# N32G457 register map
Vendor: NSING TECHNOLOGIES PTE. LTD.; File version: 1.0
Registers are 32-bit, read-write, reset 0x0 unless marked. A register's access mark holds for its fields unless they carry their own. Offsets are from the block's base; [hi:lo] are bit positions; {n}, {i} and the like mark numbered series; 'fields as' and 'values as' point back to an identical list.

## USART1 — Universal synchronous asynchronous receiver transmitter
Base 0x40013800
Same registers: USART2 0x40004400, USART3 0x40004800, UART4 0x40004C00, UART5 0x40005000, UART6 0x40015000, UART7 0x40015400
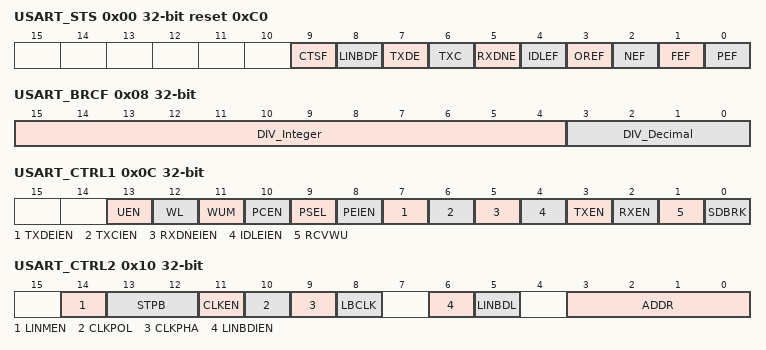
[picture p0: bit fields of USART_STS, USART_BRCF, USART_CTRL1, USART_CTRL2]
0x00 USART_STS reset 0xC0
  [9] CTSF, [8] LINBDF, [7] TXDE, [6] TXC, [5] RXDNE, [4] IDLEF, [3] OREF, [2] NEF, [1] FEF, [0] PEF
0x04 USART_DAT
  [8:0] DATV
0x08 USART_BRCF
  [15:4] DIV_Integer, [3:0] DIV_Decimal
0x0C USART_CTRL1
  [13] UEN, [12] WL, [11] WUM, [10] PCEN, [9] PSEL, [8] PEIEN, [7] TXDEIEN, [6] TXCIEN, [5] RXDNEIEN, [4] IDLEIEN, [3] TXEN, [2] RXEN, [1] RCVWU, [0] SDBRK
0x10 USART_CTRL2
  [14] LINMEN, [13:12] STPB, [11] CLKEN, [10] CLKPOL, [9] CLKPHA, [8] LBCLK, [6] LINBDIEN, [5] LINBDL, [3:0] ADDR
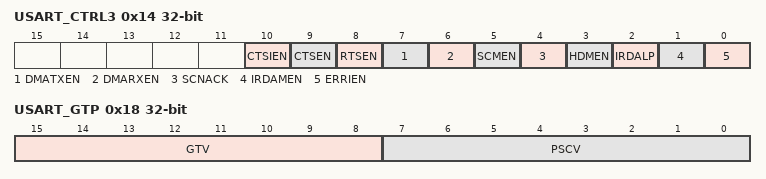
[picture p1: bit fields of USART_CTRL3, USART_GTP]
0x14 USART_CTRL3
  [10] CTSIEN, [9] CTSEN, [8] RTSEN, [7] DMATXEN, [6] DMARXEN, [5] SCMEN, [4] SCNACK, [3] HDMEN, [2] IRDALP, [1] IRDAMEN, [0] ERRIEN
0x18 USART_GTP
  [15:8] GTV, [7:0] PSCV

## USB — Universal serial bus full-speed device interface
Base 0x40005C00
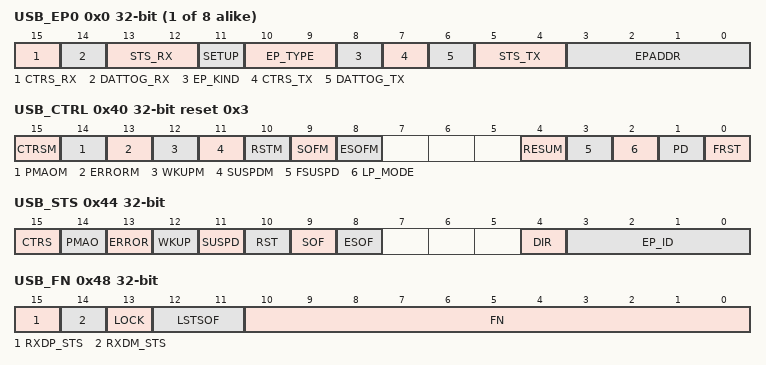
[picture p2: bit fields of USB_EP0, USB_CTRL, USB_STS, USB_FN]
{0x0+4i} USB_EP{i} (i=0..7)
  [15] CTRS_RX, [14] DATTOG_RX, [13:12] STS_RX, [11] SETUP, [10:9] EP_TYPE, [8] EP_KIND, [7] CTRS_TX, [6] DATTOG_TX, [5:4] STS_TX, [3:0] EPADDR
0x40 USB_CTRL reset 0x3
  [15] CTRSM, [14] PMAOM, [13] ERRORM, [12] WKUPM, [11] SUSPDM, [10] RSTM, [9] SOFM, [8] ESOFM, [4] RESUM, [3] FSUSPD, [2] LP_MODE, [1] PD, [0] FRST
0x44 USB_STS
  [15] CTRS, [14] PMAO, [13] ERROR, [12] WKUP, [11] SUSPD, [10] RST, [9] SOF, [8] ESOF, [4] DIR, [3:0] EP_ID
0x48 USB_FN
  [15] RXDP_STS, [14] RXDM_STS, [13] LOCK, [12:11] LSTSOF, [10:0] FN
0x4C USB_ADDR
  [6:0] ADDR
0x50 USB_BUFTAB
  [15:3] BUFTAB

## OPAMP — operational amplifier
Base 0x40002000
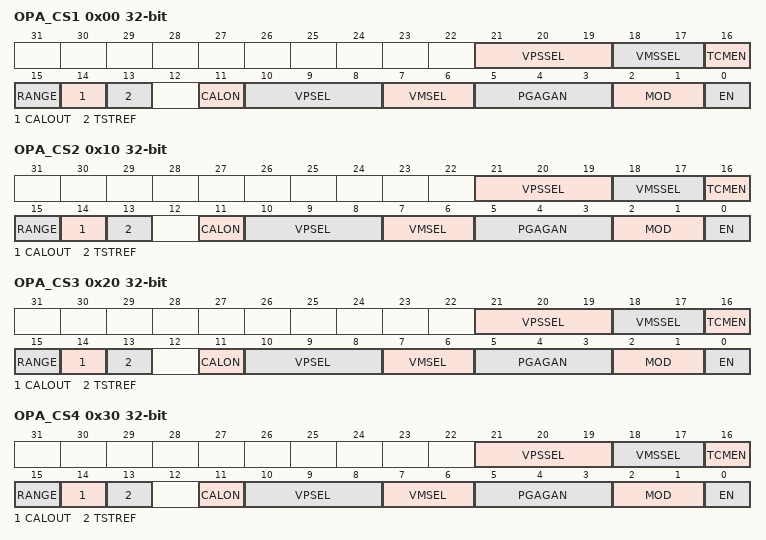
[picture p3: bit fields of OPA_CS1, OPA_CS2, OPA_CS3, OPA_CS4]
0x00 OPA_CS1
  [21:19] VPSSEL, [18:17] VMSSEL, [16] TCMEN, [15] RANGE, [14] CALOUT, [13] TSTREF, [11] CALON, [10:8] VPSEL, [7:6] VMSEL, [5:3] PGAGAN, [2:1] MOD, [0] EN
0x10 OPA_CS2
  fields as OPA_CS1
0x20 OPA_CS3
  fields as OPA_CS1
0x30 OPA_CS4
  fields as OPA_CS1
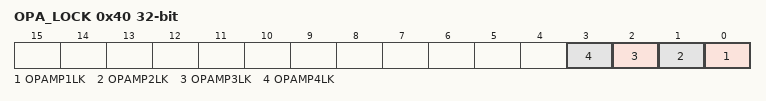
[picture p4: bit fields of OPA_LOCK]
0x40 OPA_LOCK
  [n-1] OPAMP{n}LK (n=1..4)

## COMP — comparator
Base 0x40002400
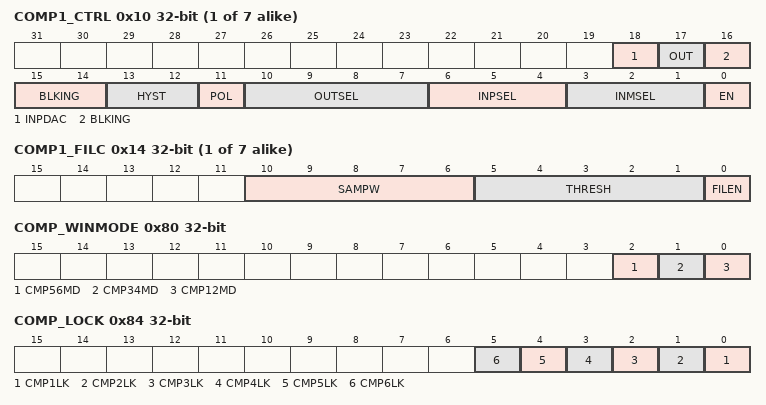
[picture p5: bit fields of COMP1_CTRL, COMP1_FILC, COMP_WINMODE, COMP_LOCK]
{0x0+0x10*i} COMP{i}_CTRL (i=1..7)
  [18] INPDAC, [17] OUT ro, [16:14] BLKING, [13:12] HYST, [11] POL, [10:7] OUTSEL, [6:4] INPSEL, [3:1] INMSEL, [0] EN
{0x4+0x10*i} COMP{i}_FILC (i=1..7)
  [10:6] SAMPW, [5:1] THRESH, [0] FILEN
{0x8+0x10*i} COMP{i}_FILP (i=1..7)
  [15:0] CLKPSC
0x80 COMP_WINMODE
  [2] CMP56MD, [1] CMP34MD, [0] CMP12MD
0x84 COMP_LOCK
  [n-1] CMP{n}LK (n=1..6)
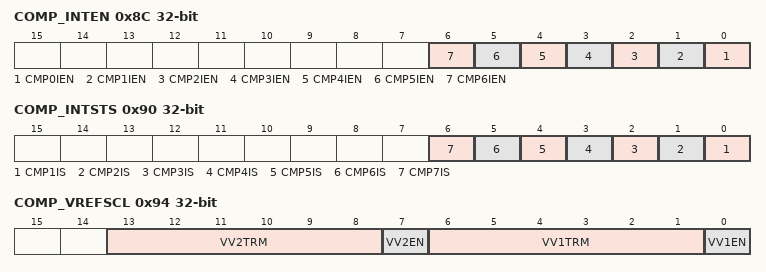
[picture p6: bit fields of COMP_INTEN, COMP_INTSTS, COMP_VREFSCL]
0x8C COMP_INTEN
  [n] CMP{n}IEN (n=0..6)
0x90 COMP_INTSTS
  [n-1] CMP{n}IS (n=1..7)
0x94 COMP_VREFSCL
  [13:8] VV2TRM, [7] VV2EN, [6:1] VV1TRM, [0] VV1EN

## TSC — touch screen control
Base 0x40003400
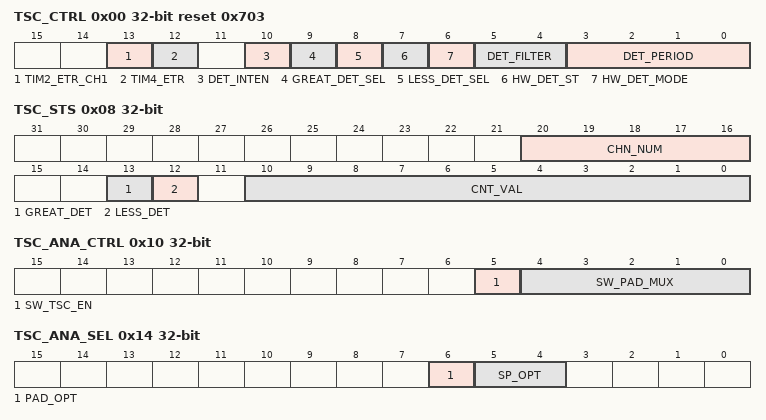
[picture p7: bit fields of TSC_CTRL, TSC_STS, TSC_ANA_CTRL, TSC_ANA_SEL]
0x00 TSC_CTRL reset 0x703
  [13] TIM2_ETR_CH1, [12] TIM4_ETR, [10] DET_INTEN, [9] GREAT_DET_SEL, [8] LESS_DET_SEL, [7] HW_DET_ST, [6] HW_DET_MODE, [5:4] DET_FILTER, [3:0] DET_PERIOD
0x04 TSC_CHNEN
  [23:0] CHN_SEL
0x08 TSC_STS
  [20:16] CHN_NUM, [13] GREAT_DET, [12] LESS_DET, [10:0] CNT_VAL
0x10 TSC_ANA_CTRL
  [5] SW_TSC_EN, [4:0] SW_PAD_MUX
0x14 TSC_ANA_SEL
  [6] PAD_OPT, [5:4] SP_OPT
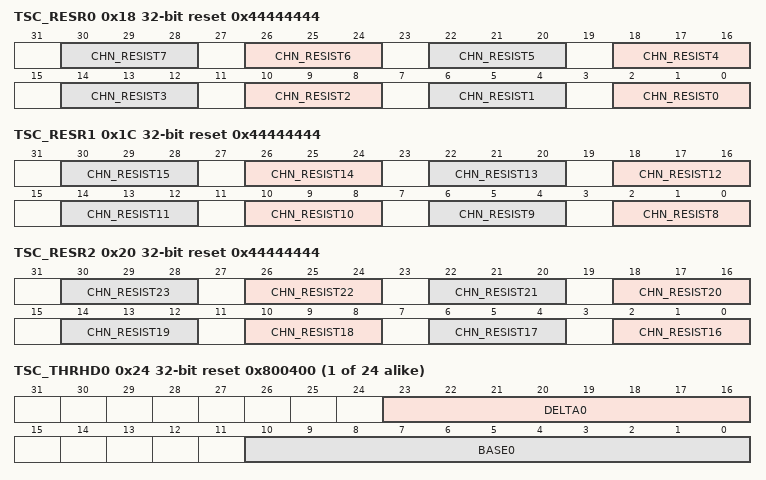
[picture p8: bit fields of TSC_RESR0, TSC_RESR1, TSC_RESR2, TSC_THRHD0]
0x18 TSC_RESR0 reset 0x44444444
  [4n+2:4n] CHN_RESIST{n} (n=0..7)
0x1C TSC_RESR1 reset 0x44444444
  [4n-30:4n-32] CHN_RESIST{n} (n=8..15)
0x20 TSC_RESR2 reset 0x44444444
  [4n-62:4n-64] CHN_RESIST{n} (n=16..23)
{0x24+4i} TSC_THRHD{i} reset 0x800400 (i=0..23)
  [23:16] DELTA{i}, [10:0] BASE{i}

## ETH — Ethernet: media access control
Base 0x40028000
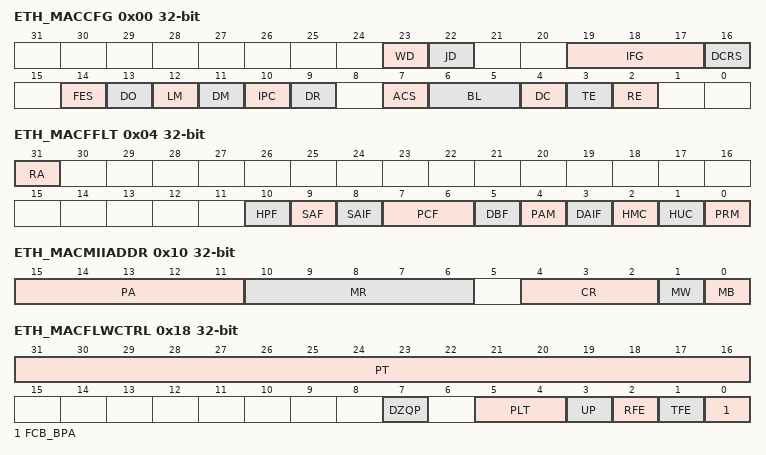
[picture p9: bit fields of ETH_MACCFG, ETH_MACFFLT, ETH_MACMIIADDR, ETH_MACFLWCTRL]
0x00 ETH_MACCFG
  [23] WD, [22] JD, [19:17] IFG, [16] DCRS, [14] FES, [13] DO, [12] LM, [11] DM, [10] IPC, [9] DR, [7] ACS, [6:5] BL, [4] DC, [3] TE, [2] RE
0x04 ETH_MACFFLT
  [31] RA, [10] HPF, [9] SAF, [8] SAIF, [7:6] PCF, [5] DBF, [4] PAM, [3] DAIF, [2] HMC, [1] HUC, [0] PRM
0x08 ETH_MACHASHHI
  [31:0] HTH
0x0C ETH_MACHASHLO
  [31:0] HTL
0x10 ETH_MACMIIADDR
  [15:11] PA, [10:6] MR, [4:2] CR, [1] MW, [0] MB
0x14 ETH_MACMIIDAT
  [15:0] MD
0x18 ETH_MACFLWCTRL
  [31:16] PT, [7] DZQP, [5:4] PLT, [3] UP, [2] RFE, [1] TFE, [0] FCB_BPA
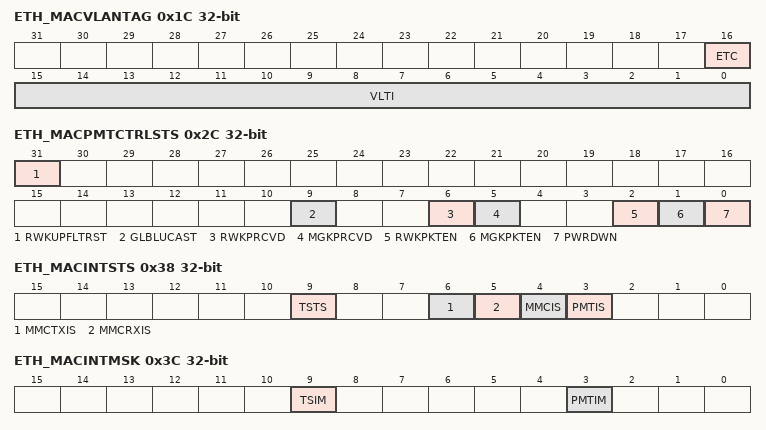
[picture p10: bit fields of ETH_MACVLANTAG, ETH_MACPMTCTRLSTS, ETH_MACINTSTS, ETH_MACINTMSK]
0x1C ETH_MACVLANTAG
  [16] ETC, [15:0] VLTI
0x28 ETH_MACRMTWUFRMFLT
  [31:0] DAT
0x2C ETH_MACPMTCTRLSTS
  [31] RWKUPFLTRST, [9] GLBLUCAST, [6] RWKPRCVD, [5] MGKPRCVD, [2] RWKPKTEN, [1] MGKPKTEN, [0] PWRDWN
0x38 ETH_MACINTSTS
  [9] TSTS, [6] MMCTXIS, [5] MMCRXIS, [4] MMCIS, [3] PMTIS
0x3C ETH_MACINTMSK
  [9] TSIM, [3] PMTIM
0x40 ETH_MACADDR0HI reset 0xFFFF
  [15:0] ADDRHI
{0x44+8i} ETH_MACADDR{i}LO reset 0xFFFFFFFF (i=0..3)
  [31:0] ADDRLO
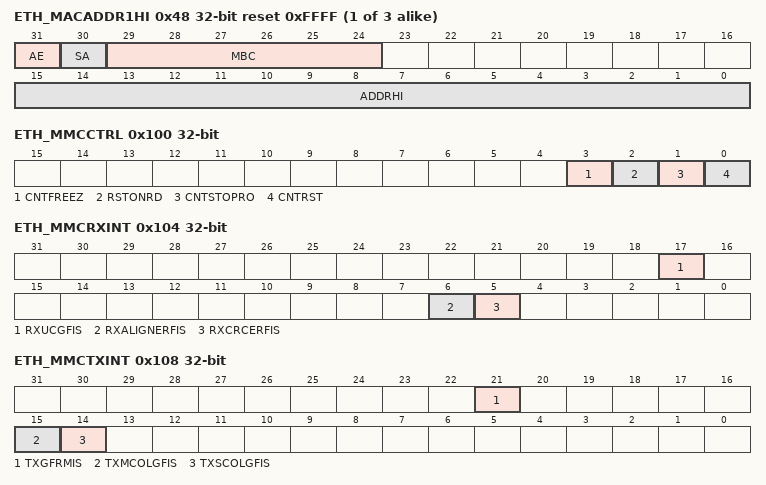
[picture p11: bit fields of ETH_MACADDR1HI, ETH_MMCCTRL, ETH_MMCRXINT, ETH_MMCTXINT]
{0x40+8i} ETH_MACADDR{i}HI reset 0xFFFF (i=1..3)
  [31] AE, [30] SA, [29:24] MBC, [15:0] ADDRHI
0x100 ETH_MMCCTRL
  [3] CNTFREEZ, [2] RSTONRD, [1] CNTSTOPRO, [0] CNTRST
0x104 ETH_MMCRXINT
  [17] RXUCGFIS, [6] RXALIGNERFIS, [5] RXCRCERFIS
0x108 ETH_MMCTXINT
  [21] TXGFRMIS, [15] TXMCOLGFIS, [14] TXSCOLGFIS
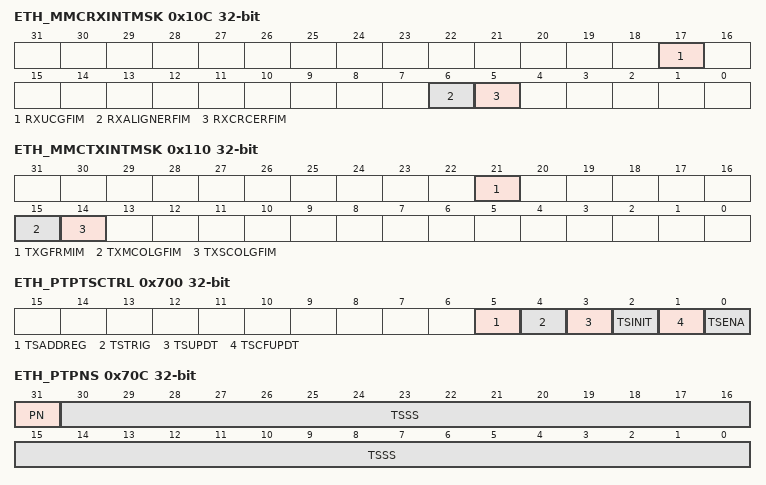
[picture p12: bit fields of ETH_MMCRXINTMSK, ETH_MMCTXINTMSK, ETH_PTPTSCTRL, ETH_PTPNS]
0x10C ETH_MMCRXINTMSK
  [17] RXUCGFIM, [6] RXALIGNERFIM, [5] RXCRCERFIM
0x110 ETH_MMCTXINTMSK
  [21] TXGFRMIM, [15] TXMCOLGFIM, [14] TXSCOLGFIM
0x14C ETH_MMCTXGFASCCNT
  [31:0] CNT
0x150 ETH_MMCTXGFAMSCCNT
  [31:0] CNT
0x168 ETH_MMCTXGFCNT
  [31:0] CNT
0x194 ETH_MMCRXFCECNT
  [31:0] CNT
0x198 ETH_MMCRXFAECNT
  [31:0] CNT
0x1C4 ETH_MMCRXGUFCNT
  [31:0] CNT
0x700 ETH_PTPTSCTRL
  [5] TSADDREG, [4] TSTRIG, [3] TSUPDT, [2] TSINIT, [1] TSCFUPDT, [0] TSENA
0x704 ETH_PTPSSINC
  [7:0] SSINC
0x708 ETH_PTPSEC
  [31:0] TSS
0x70C ETH_PTPNS
  [31] PN, [30:0] TSSS
0x710 ETH_PTPSECUP
  [31:0] TSS
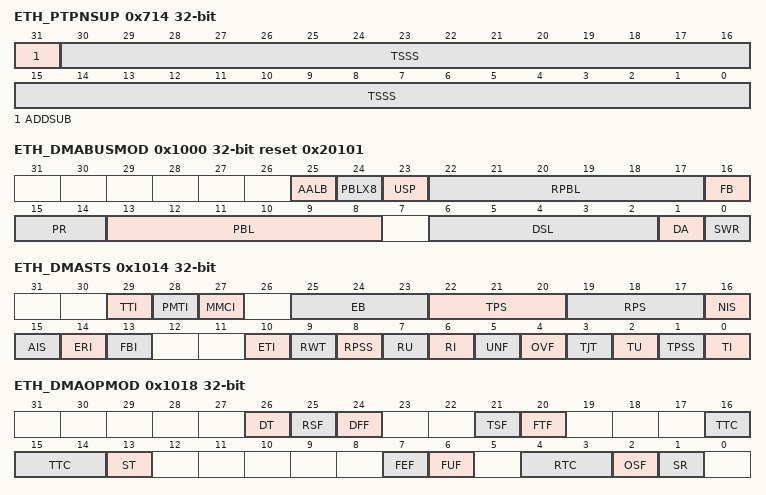
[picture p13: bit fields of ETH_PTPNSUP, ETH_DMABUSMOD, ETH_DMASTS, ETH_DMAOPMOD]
0x714 ETH_PTPNSUP
  [31] ADDSUB, [30:0] TSSS
0x718 ETH_PTPTSADD
  [31:0] TSA
0x71C ETH_PTPTTSEC
  [31:0] TTS
0x720 ETH_PTPTTNS
  [31:0] TTSLO
0x1000 ETH_DMABUSMOD reset 0x20101
  [25] AALB, [24] PBLX8, [23] USP, [22:17] RPBL, [16] FB, [15:14] PR, [13:8] PBL, [6:2] DSL, [1] DA, [0] SWR
0x1004 ETH_DMATXPD
  [31:0] TPD
0x1008 ETH_DMARXPD
  [31:0] RPD
0x100C ETH_DMARXDLADDR
  [31:0] SRL
0x1010 ETH_DMATXDLADDR
  [31:0] STL
0x1014 ETH_DMASTS
  [29] TTI, [28] PMTI, [27] MMCI, [25:23] EB, [22:20] TPS, [19:17] RPS, [16] NIS, [15] AIS, [14] ERI, [13] FBI, [10] ETI, [9] RWT, [8] RPSS, [7] RU, [6] RI, [5] UNF, [4] OVF, [3] TJT, [2] TU, [1] TPSS, [0] TI
0x1018 ETH_DMAOPMOD
  [26] DT, [25] RSF, [24] DFF, [21] TSF, [20] FTF, [16:14] TTC, [13] ST, [7] FEF, [6] FUF, [4:3] RTC, [2] OSF, [1] SR
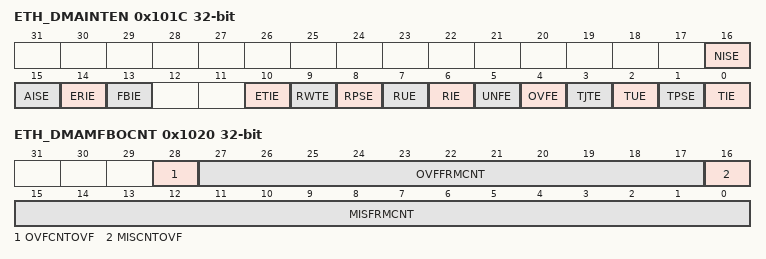
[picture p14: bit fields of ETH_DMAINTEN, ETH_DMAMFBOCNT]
0x101C ETH_DMAINTEN
  [16] NISE, [15] AISE, [14] ERIE, [13] FBIE, [10] ETIE, [9] RWTE, [8] RPSE, [7] RUE, [6] RIE, [5] UNFE, [4] OVFE, [3] TJTE, [2] TUE, [1] TPSE, [0] TIE
0x1020 ETH_DMAMFBOCNT
  [28] OVFCNTOVF, [27:17] OVFFRMCNT, [16] MISCNTOVF, [15:0] MISFRMCNT
0x1048 ETH_DMACHTXDESC
  [31:0] ADDR
0x104C ETH_DMACHRXDESC
  [31:0] ADDR
0x1050 ETH_DMACHTXBADDR
  [31:0] ADDR
0x1054 ETH_DMACHRXBADDR
  [31:0] ADDR

## DVP — Digital video port
Base 0x40014C00
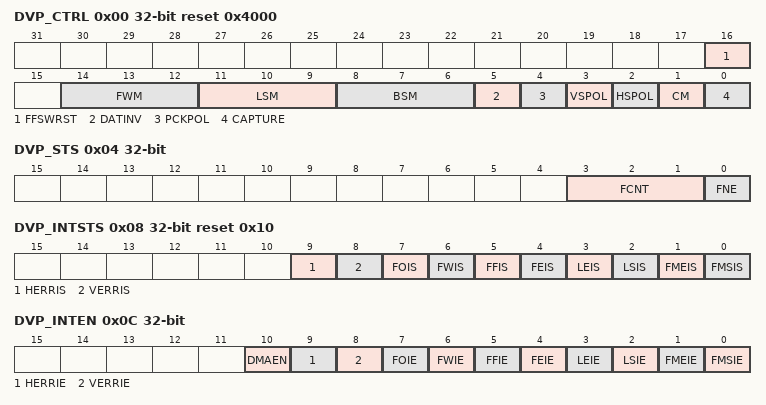
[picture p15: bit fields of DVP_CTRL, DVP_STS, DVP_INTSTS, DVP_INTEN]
0x00 DVP_CTRL reset 0x4000 (reset mask 0xFFFF)
  [16] FFSWRST, [14:12] FWM, [11:9] LSM, [8:6] BSM, [5] DATINV, [4] PCKPOL, [3] VSPOL, [2] HSPOL, [1] CM, [0] CAPTURE
0x04 DVP_STS
  [3:1] FCNT, [0] FNE
0x08 DVP_INTSTS reset 0x10
  [9] HERRIS, [8] VERRIS, [7] FOIS, [6] FWIS, [5] FFIS, [4] FEIS, [3] LEIS, [2] LSIS, [1] FMEIS, [0] FMSIS
0x0C DVP_INTEN
  [10] DMAEN, [9] HERRIE, [8] VERRIE, [7] FOIE, [6] FWIE, [5] FFIE, [4] FEIE, [3] LEIE, [2] LSIE, [1] FMEIE, [0] FMSIE
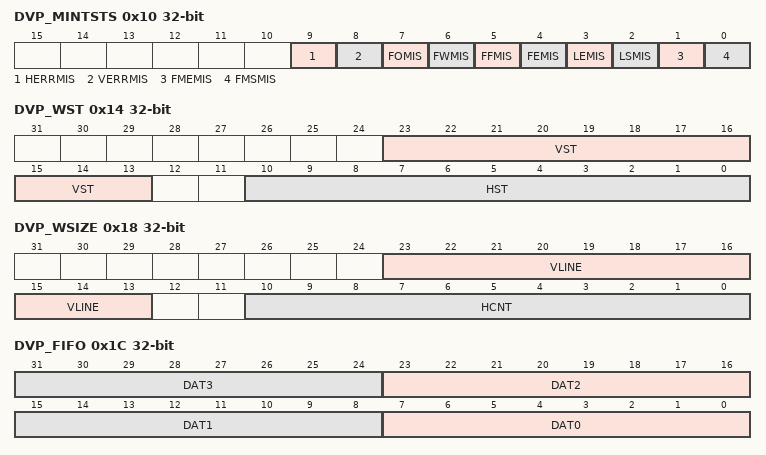
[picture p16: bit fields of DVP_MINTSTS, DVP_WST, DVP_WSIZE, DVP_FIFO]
0x10 DVP_MINTSTS
  [9] HERRMIS, [8] VERRMIS, [7] FOMIS, [6] FWMIS, [5] FFMIS, [4] FEMIS, [3] LEMIS, [2] LSMIS, [1] FMEMIS, [0] FMSMIS
0x14 DVP_WST
  [23:13] VST, [10:0] HST
0x18 DVP_WSIZE
  [23:13] VLINE, [10:0] HCNT
0x1C DVP_FIFO
  [8n+7:8n] DAT{n} (n=0..3)

## WWDG — window watchdog
Base 0x40002C00
0x00 WWDG_CTRL reset 0x7F
  [7] ACTB, [6:0] T
0x04 WWDG_CFG reset 0x7F
  [9] EWINT, [8:7] TIMERB, [6:0] W
0x08 WWDG_STS
  [0] EWINTF
